CM_ "Identical to _honda_common except removed lkas_hud";

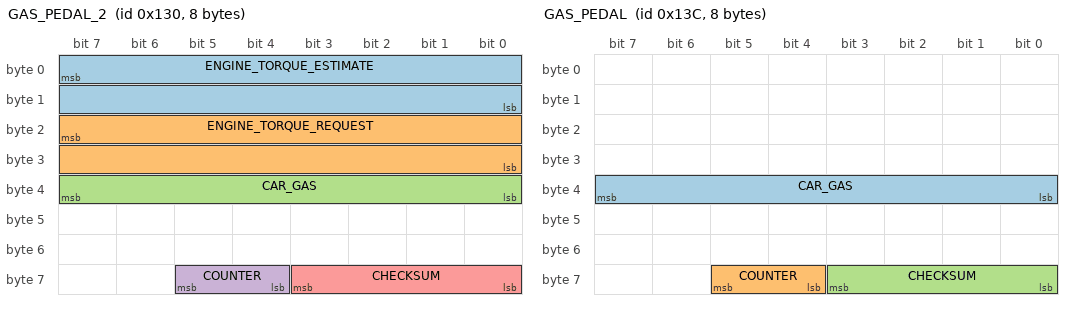
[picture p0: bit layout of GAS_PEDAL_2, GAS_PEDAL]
BO_ 304 GAS_PEDAL_2: 8 PCM
 SG_ ENGINE_TORQUE_ESTIMATE : 7|16@0- (1,0) [-1000|1000] "Nm" EON
 SG_ ENGINE_TORQUE_REQUEST : 23|16@0- (1,0) [-1000|1000] "Nm" EON
 SG_ CAR_GAS : 39|8@0+ (1,0) [0|255] "" EON
 SG_ COUNTER : 61|2@0+ (1,0) [0|3] "" EON
 SG_ CHECKSUM : 59|4@0+ (1,0) [0|15] "" EON

BO_ 316 GAS_PEDAL: 8 PCM
 SG_ CAR_GAS : 39|8@0+ (1,0) [0|255] "" EON
 SG_ COUNTER : 61|2@0+ (1,0) [0|3] "" EON
 SG_ CHECKSUM : 59|4@0+ (1,0) [0|15] "" EON

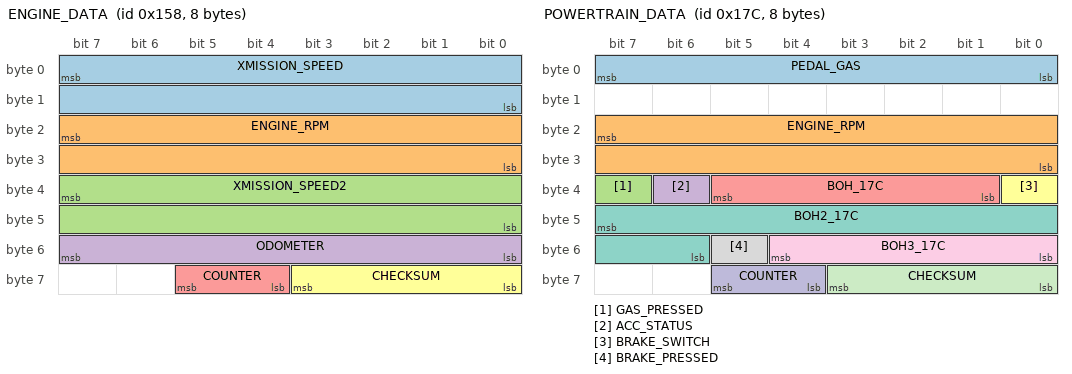
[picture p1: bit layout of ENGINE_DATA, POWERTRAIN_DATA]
BO_ 344 ENGINE_DATA: 8 PCM
 SG_ XMISSION_SPEED : 7|16@0+ (0.01,0) [0|250] "kph" EON
 SG_ ENGINE_RPM : 23|16@0+ (1,0) [0|15000] "rpm" EON
 SG_ XMISSION_SPEED2 : 39|16@0+ (0.01,0) [0|250] "kph" EON
 SG_ ODOMETER : 55|8@0+ (10,0) [0|2550] "m" XXX
 SG_ COUNTER : 61|2@0+ (1,0) [0|3] "" EON
 SG_ CHECKSUM : 59|4@0+ (1,0) [0|15] "" EON

BO_ 380 POWERTRAIN_DATA: 8 PCM
 SG_ PEDAL_GAS : 7|8@0+ (1,0) [0|255] "" EON
 SG_ ENGINE_RPM : 23|16@0+ (1,0) [0|15000] "rpm" EON
 SG_ GAS_PRESSED : 39|1@0+ (1,0) [0|1] "" EON
 SG_ ACC_STATUS : 38|1@0+ (1,0) [0|1] "" EON
 SG_ BOH_17C : 37|5@0+ (1,0) [0|1] "" EON
 SG_ BRAKE_SWITCH : 32|1@0+ (1,0) [0|1] "" EON
 SG_ BOH2_17C : 47|10@0+ (1,0) [0|1] "" EON
 SG_ BRAKE_PRESSED : 53|1@0+ (1,0) [0|1] "" EON
 SG_ BOH3_17C : 52|5@0+ (1,0) [0|1] "" EON
 SG_ COUNTER : 61|2@0+ (1,0) [0|3] "" EON
 SG_ CHECKSUM : 59|4@0+ (1,0) [0|15] "" EON

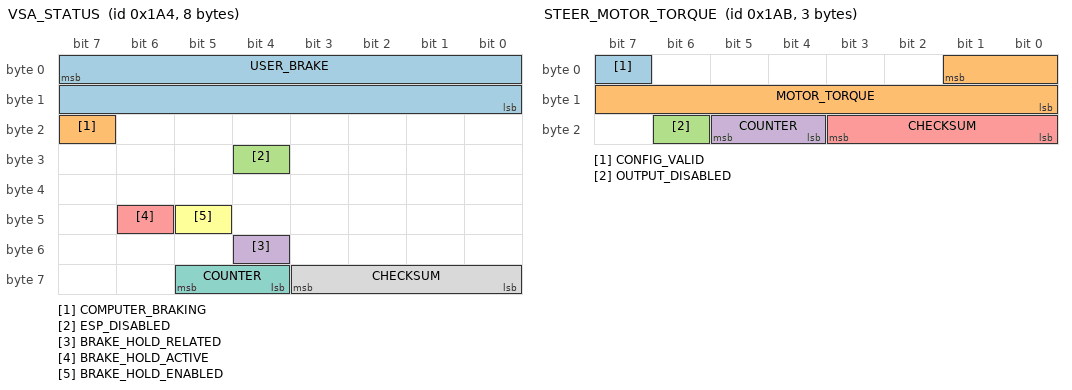
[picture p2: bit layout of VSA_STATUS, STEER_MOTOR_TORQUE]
BO_ 420 VSA_STATUS: 8 VSA
 SG_ USER_BRAKE : 7|16@0+ (0.015625,-1.609375) [0|1000] "" EON
 SG_ COMPUTER_BRAKING : 23|1@0+ (1,0) [0|1] "" EON
 SG_ ESP_DISABLED : 28|1@0+ (1,0) [0|1] "" EON
 SG_ BRAKE_HOLD_RELATED : 52|1@0+ (1,0) [0|1] "" XXX
 SG_ BRAKE_HOLD_ACTIVE : 46|1@0+ (1,0) [0|1] "" EON
 SG_ BRAKE_HOLD_ENABLED : 45|1@0+ (1,0) [0|1] "" EON
 SG_ COUNTER : 61|2@0+ (1,0) [0|3] "" EON
 SG_ CHECKSUM : 59|4@0+ (1,0) [0|15] "" EON

BO_ 427 STEER_MOTOR_TORQUE: 3 EPS
 SG_ CONFIG_VALID : 7|1@0+ (1,0) [0|1] "" EON
 SG_ MOTOR_TORQUE : 1|10@0+ (1,0) [0|256] "" EON
 SG_ OUTPUT_DISABLED : 22|1@0+ (1,0) [0|1] "" EON
 SG_ COUNTER : 21|2@0+ (1,0) [0|3] "" EON
 SG_ CHECKSUM : 19|4@0+ (1,0) [0|15] "" EON

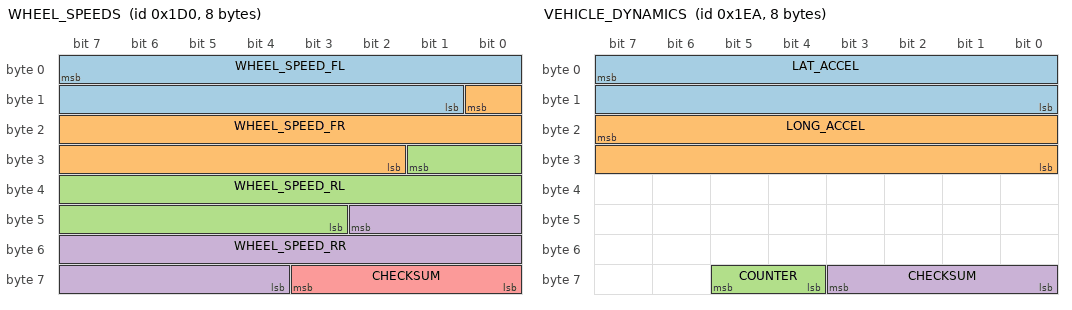
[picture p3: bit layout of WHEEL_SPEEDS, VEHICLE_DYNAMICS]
BO_ 464 WHEEL_SPEEDS: 8 VSA
 SG_ WHEEL_SPEED_FL : 7|15@0+ (0.01,0) [0|250] "kph" EON
 SG_ WHEEL_SPEED_FR : 8|15@0+ (0.01,0) [0|250] "kph" EON
 SG_ WHEEL_SPEED_RL : 25|15@0+ (0.01,0) [0|250] "kph" EON
 SG_ WHEEL_SPEED_RR : 42|15@0+ (0.01,0) [0|250] "kph" EON
 SG_ CHECKSUM : 59|4@0+ (1,0) [0|3] "" EON

BO_ 490 VEHICLE_DYNAMICS: 8 VSA
 SG_ LAT_ACCEL : 7|16@0- (0.0015,0) [-20|20] "m/s2" EON
 SG_ LONG_ACCEL : 23|16@0- (0.0015,0) [-20|20] "m/s2" EON
 SG_ COUNTER : 61|2@0+ (1,0) [0|3] "" EON
 SG_ CHECKSUM : 59|4@0+ (1,0) [0|3] "" EON

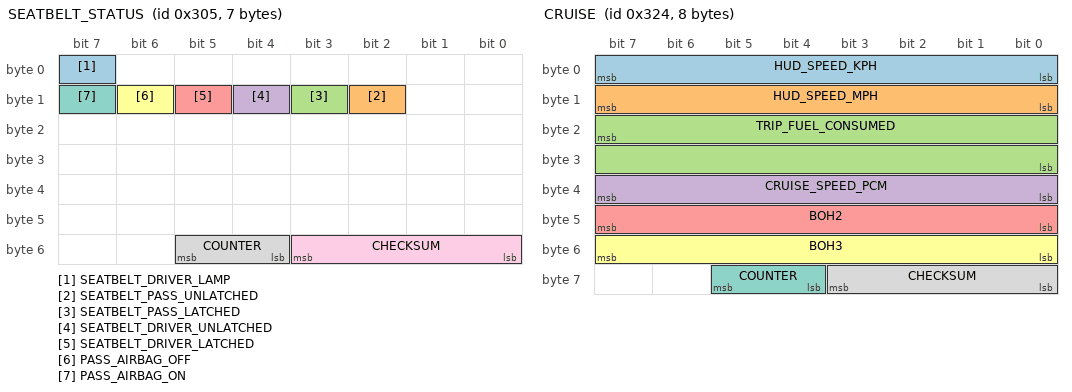
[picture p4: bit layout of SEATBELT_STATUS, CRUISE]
BO_ 773 SEATBELT_STATUS: 7 BDY
 SG_ SEATBELT_DRIVER_LAMP : 7|1@0+ (1,0) [0|1] "" EON
 SG_ SEATBELT_PASS_UNLATCHED : 10|1@0+ (1,0) [0|1] "" EON
 SG_ SEATBELT_PASS_LATCHED : 11|1@0+ (1,0) [0|1] "" EON
 SG_ SEATBELT_DRIVER_UNLATCHED : 12|1@0+ (1,0) [0|1] "" EON
 SG_ SEATBELT_DRIVER_LATCHED : 13|1@0+ (1,0) [0|1] "" EON
 SG_ PASS_AIRBAG_OFF : 14|1@0+ (1,0) [0|1] "" EON
 SG_ PASS_AIRBAG_ON : 15|1@0+ (1,0) [0|1] "" EON
 SG_ COUNTER : 53|2@0+ (1,0) [0|3] "" EON
 SG_ CHECKSUM : 51|4@0+ (1,0) [0|3] "" EON

BO_ 804 CRUISE: 8 PCM
 SG_ HUD_SPEED_KPH : 7|8@0+ (1,0) [0|255] "kph" EON
 SG_ HUD_SPEED_MPH : 15|8@0+ (1,0) [0|255] "mph" EON
 SG_ TRIP_FUEL_CONSUMED : 23|16@0+ (1,0) [0|255] "" EON
 SG_ CRUISE_SPEED_PCM : 39|8@0+ (1,0) [0|255] "" EON
 SG_ BOH2 : 47|8@0- (1,0) [0|255] "" EON
 SG_ BOH3 : 55|8@0+ (1,0) [0|255] "" EON
 SG_ COUNTER : 61|2@0+ (1,0) [0|3] "" EON
 SG_ CHECKSUM : 59|4@0+ (1,0) [0|15] "" EON

BO_ 829 LKAS_HUD: 5 ADAS
 SG_ CAM_TEMP_HIGH : 7|1@0+ (1,0) [0|255] "" BDY
 SG_ SET_ME_X41 : 6|7@0+ (1,0) [0|127] "" BDY
 SG_ BOH : 6|7@0+ (1,0) [0|127] "" BDY
 SG_ DASHED_LANES : 14|1@0+ (1,0) [0|1] "" BDY
 SG_ DTC : 13|1@0+ (1,0) [0|1] "" BDY
 SG_ LKAS_PROBLEM : 12|1@0+ (1,0) [0|1] "" BDY
 SG_ LKAS_OFF : 11|1@0+ (1,0) [0|1] "" BDY
 SG_ SOLID_LANES : 10|1@0+ (1,0) [0|1] "" BDY
 SG_ LDW_RIGHT : 9|1@0+ (1,0) [0|1] "" BDY
 SG_ STEERING_REQUIRED : 8|1@0+ (1,0) [0|1] "" BDY
 SG_ BOH : 23|2@0+ (1,0) [0|4] "" BDY
 SG_ LDW_PROBLEM : 21|1@0+ (1,0) [0|1] "" BDY
 SG_ BEEP : 17|2@0+ (1,0) [0|1] "" BDY
 SG_ LDW_ON : 28|1@0+ (1,0) [0|1] "" BDY
 SG_ LDW_OFF : 27|1@0+ (1,0) [0|1] "" BDY
 SG_ CLEAN_WINDSHIELD : 26|1@0+ (1,0) [0|1] "" BDY
 SG_ SET_ME_X48 : 31|8@0+ (1,0) [0|255] "" BDY
 SG_ COUNTER : 37|2@0+ (1,0) [0|3] "" BDY
 SG_ CHECKSUM : 35|4@0+ (1,0) [0|15] "" BDY

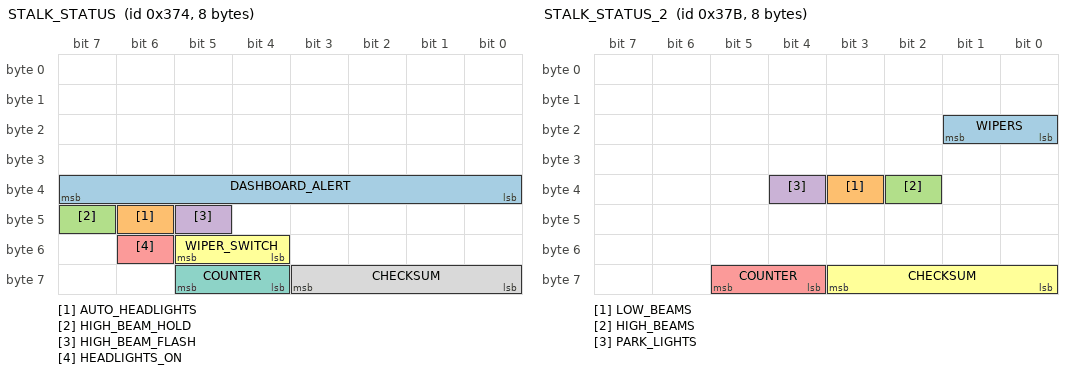
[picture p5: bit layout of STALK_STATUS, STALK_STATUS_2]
BO_ 884 STALK_STATUS: 8 XXX
 SG_ DASHBOARD_ALERT : 39|8@0+ (1,0) [0|255] "" EON
 SG_ AUTO_HEADLIGHTS : 46|1@0+ (1,0) [0|1] "" EON
 SG_ HIGH_BEAM_HOLD : 47|1@0+ (1,0) [0|1] "" EON
 SG_ HIGH_BEAM_FLASH : 45|1@0+ (1,0) [0|1] "" EON
 SG_ HEADLIGHTS_ON : 54|1@0+ (1,0) [0|1] "" EON
 SG_ WIPER_SWITCH : 53|2@0+ (1,0) [0|3] "" XXX
 SG_ COUNTER : 61|2@0+ (1,0) [0|3] "" EON
 SG_ CHECKSUM : 59|4@0+ (1,0) [0|15] "" EON

BO_ 891 STALK_STATUS_2: 8 XXX
 SG_ WIPERS : 17|2@0+ (1,0) [0|3] "" EON
 SG_ LOW_BEAMS : 35|1@0+ (1,0) [0|1] "" XXX
 SG_ HIGH_BEAMS : 34|1@0+ (1,0) [0|1] "" XXX
 SG_ PARK_LIGHTS : 36|1@0+ (1,0) [0|1] "" XXX
 SG_ COUNTER : 61|2@0+ (1,0) [0|3] "" EON
 SG_ CHECKSUM : 59|4@0+ (1,0) [0|15] "" EON

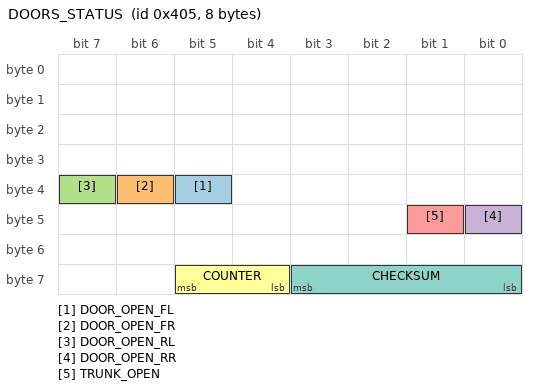
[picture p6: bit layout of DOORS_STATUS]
BO_ 1029 DOORS_STATUS: 8 BDY
 SG_ DOOR_OPEN_FL : 37|1@0+ (1,0) [0|1] "" EON
 SG_ DOOR_OPEN_FR : 38|1@0+ (1,0) [0|1] "" EON
 SG_ DOOR_OPEN_RL : 39|1@0+ (1,0) [0|1] "" EON
 SG_ DOOR_OPEN_RR : 40|1@0+ (1,0) [0|1] "" EON
 SG_ TRUNK_OPEN : 41|1@0+ (1,0) [0|1] "" EON
 SG_ COUNTER : 61|2@0+ (1,0) [0|3] "" EON
 SG_ CHECKSUM : 59|4@0+ (1,0) [0|15] "" EON

CM_ SG_ 304 "Seems to be platform-agnostic";
CM_ SG_ 316 "Should exist on Nidec";
CM_ SG_ 420 BRAKE_HOLD_RELATED "On when Brake Hold engaged";
CM_ SG_ 490 LONG_ACCEL "wheel speed derivative, noisy and zero snapping";
CM_ SG_ 773 PASS_AIRBAG_ON "Might just be indicator light";
CM_ SG_ 773 PASS_AIRBAG_OFF "Might just be indicator light";
CM_ SG_ 804 CRUISE_SPEED_PCM "255 = no speed";
CM_ SG_ 829 BEEP "beeps are pleasant, chimes are for warnngs etc...";

VAL_ 829 BEEP 3 "single_beep" 2 "triple_beep" 1 "repeated_beep" 0 "no_beep";
VAL_ 884 DASHBOARD_ALERT 0 "none" 51 "acc_problem" 55 "cmbs_problem" 75 "key_not_detected" 79 "fasten_seatbelt" 111 "lkas_problem" 131 "brake_system_problem" 132 "brake_hold_problem" 139 "tbd" 161 "door_open";
VAL_ 891 WIPERS 4 "High" 2 "Low" 0 "Off";
